# STM32F405RGT6 register map
Vendor: STMicroelectronics; File version: 0.1.0
CPU: Cortex-M4 r0p1, little endian, MPU, FPU, DSP, VTOR, 4 interrupt priority bits
Registers are 32-bit, read-write, reset 0x0 unless marked. A register's access mark holds for its fields unless they carry their own. Offsets are from the block's base; [hi:lo] are bit positions; {n}, {i} and the like mark numbered series.

## RNG — Random number generator
Base 0x50060800
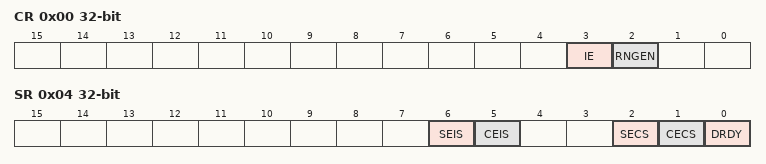
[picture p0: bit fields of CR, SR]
0x00 CR — control register
  [3] IE — Interrupt enable
  [2] RNGEN — Random number generator enable
0x04 SR access per field — status register
  [6] SEIS rw — Seed error interrupt status
  [5] CEIS rw — Clock error interrupt status
  [2] SECS ro — Seed error current status
  [1] CECS ro — Clock error current status
  [0] DRDY ro — Data ready
0x08 DR ro — data register
  [31:0] RNDATA — Random data

## DBGMCU — Debug support
Base 0xE0042000
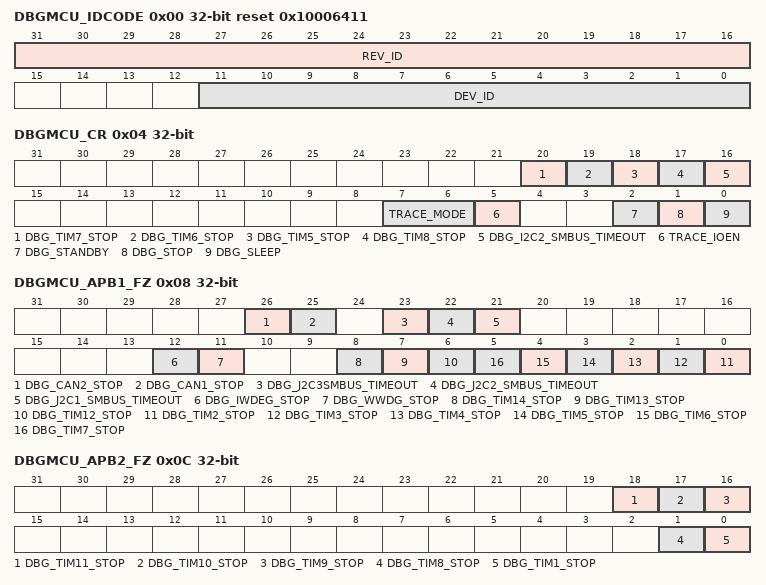
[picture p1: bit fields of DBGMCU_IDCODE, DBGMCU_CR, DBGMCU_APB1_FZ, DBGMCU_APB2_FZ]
0x00 DBGMCU_IDCODE ro reset 0x10006411 — IDCODE
  [31:16] REV_ID, [11:0] DEV_ID
0x04 DBGMCU_CR — Control Register
  [20] DBG_TIM7_STOP, [19] DBG_TIM6_STOP, [18] DBG_TIM5_STOP, [17] DBG_TIM8_STOP, [16] DBG_I2C2_SMBUS_TIMEOUT, [7:6] TRACE_MODE, [5] TRACE_IOEN, [2] DBG_STANDBY, [1] DBG_STOP, [0] DBG_SLEEP
0x08 DBGMCU_APB1_FZ — Debug MCU APB1 Freeze registe
  [26] DBG_CAN2_STOP, [25] DBG_CAN1_STOP, [23] DBG_J2C3SMBUS_TIMEOUT, [22] DBG_J2C2_SMBUS_TIMEOUT, [21] DBG_J2C1_SMBUS_TIMEOUT, [12] DBG_IWDEG_STOP, [11] DBG_WWDG_STOP, [8] DBG_TIM14_STOP, [7] DBG_TIM13_STOP, [6] DBG_TIM12_STOP, [n-2] DBG_TIM{n}_STOP (n=2..7)
0x0C DBGMCU_APB2_FZ — Debug MCU APB2 Freeze registe
  [18] DBG_TIM11_STOP — TIM11 counter stopped when core is halted
  [17] DBG_TIM10_STOP — TIM10 counter stopped when core is halted
  [16] DBG_TIM9_STOP — TIM9 counter stopped when core is halted
  [1] DBG_TIM8_STOP — TIM8 counter stopped when core is halted
  [0] DBG_TIM1_STOP — TIM1 counter stopped when core is halted

## GPIOI — General-purpose I/Os
Base 0x40022000
Same registers: GPIOC 0x40020800, GPIOD 0x40020C00, GPIOE 0x40021000, GPIOF 0x40021400, GPIOG 0x40021800, GPIOH 0x40021C00
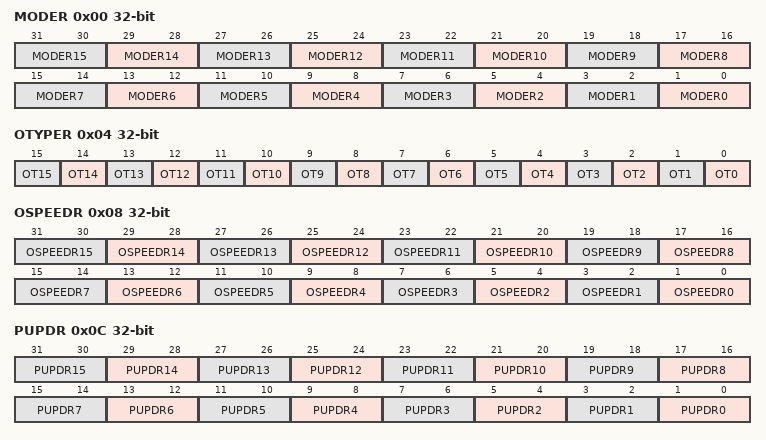
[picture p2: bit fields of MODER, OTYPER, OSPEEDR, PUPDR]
0x00 MODER — GPIO port mode register
  [2n+1:2n] MODER{n} (n=0..15) — Port x configuration bits (y = 0..15)
0x04 OTYPER — GPIO port output type register
  [n] OT{n} (n=0..15) — Port x configuration bits (y = 0..15)
0x08 OSPEEDR — GPIO port output speed register
  [2n+1:2n] OSPEEDR{n} (n=0..15) — Port x configuration bits (y = 0..15)
0x0C PUPDR — GPIO port pull-up/pull-down register
  [2n+1:2n] PUPDR{n} (n=0..15) — Port x configuration bits (y = 0..15)
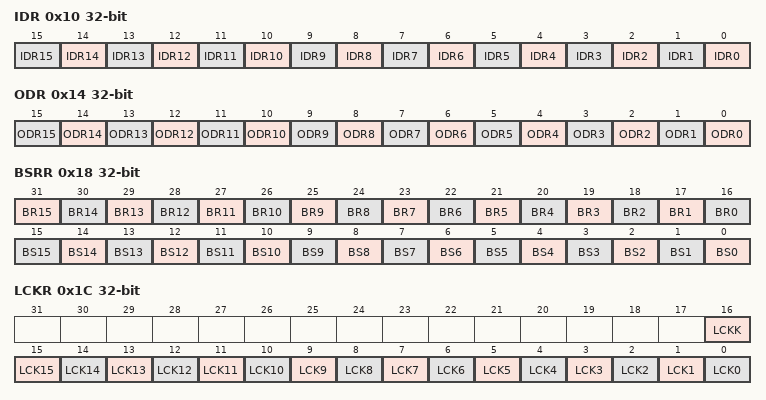
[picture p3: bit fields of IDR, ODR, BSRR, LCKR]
0x10 IDR ro — GPIO port input data register
  [n] IDR{n} (n=0..15) — Port input data (y = 0..15)
0x14 ODR — GPIO port output data register
  [n] ODR{n} (n=0..15) — Port output data (y = 0..15)
0x18 BSRR wo — GPIO port bit set/reset register
  [n+16] BR{n} (n=1..15) — Port x reset bit y (y = 0..15)
  [16] BR0 — Port x set bit y (y= 0..15)
  [n] BS{n} (n=0..15) — Port x set bit y (y= 0..15)
0x1C LCKR — GPIO port configuration lock register
  [16] LCKK — Port x lock bit y (y= 0..15)
  [n] LCK{n} (n=0..15) — Port x lock bit y (y= 0..15)
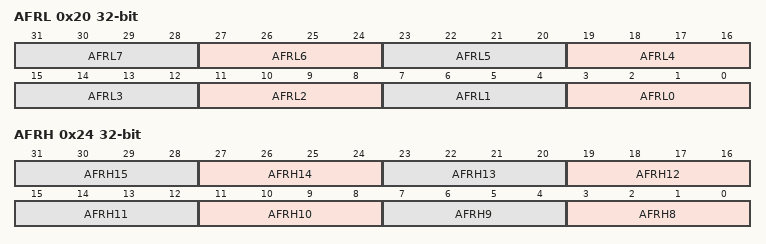
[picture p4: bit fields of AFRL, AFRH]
0x20 AFRL — GPIO alternate function low register
  [4n+3:4n] AFRL{n} (n=0..7) — Alternate function selection for port x bit y (y = 0..7)
0x24 AFRH — GPIO alternate function high register
  [4n-29:4n-32] AFRH{n} (n=8..15) — Alternate function selection for port x bit y (y = 8..15)

## GPIOB — General-purpose I/Os
Base 0x40020400
Registers as GPIOI; these are added or differ:
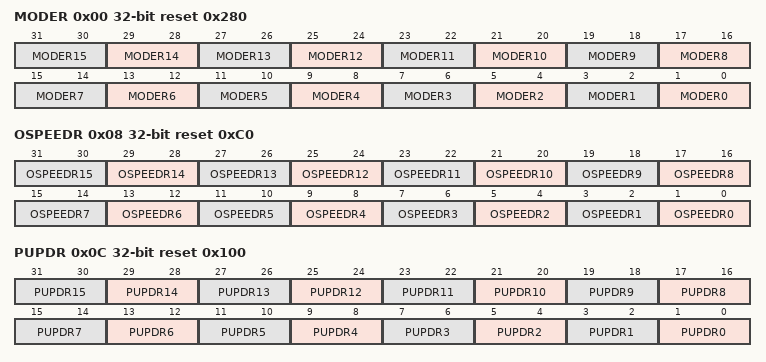
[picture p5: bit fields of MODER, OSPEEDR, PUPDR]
0x00 MODER reset 0x280 — GPIO port mode register
  [2n+1:2n] MODER{n} (n=0..15) — Port x configuration bits (y = 0..15)
0x08 OSPEEDR reset 0xC0 — GPIO port output speed register
  [2n+1:2n] OSPEEDR{n} (n=0..15) — Port x configuration bits (y = 0..15)
0x0C PUPDR reset 0x100 — GPIO port pull-up/pull-down register
  [2n+1:2n] PUPDR{n} (n=0..15) — Port x configuration bits (y = 0..15)

## GPIOA — General-purpose I/Os
Base 0x40020000
Registers as GPIOI; these are added or differ:
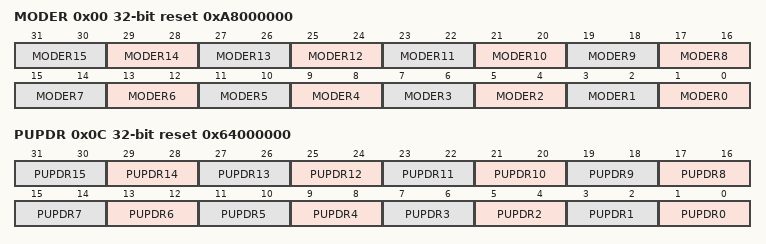
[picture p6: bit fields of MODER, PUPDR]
0x00 MODER reset 0xA8000000 — GPIO port mode register
  [2n+1:2n] MODER{n} (n=0..15) — Port x configuration bits (y = 0..15)
0x0C PUPDR reset 0x64000000 — GPIO port pull-up/pull-down register
  [2n+1:2n] PUPDR{n} (n=0..15) — Port x configuration bits (y = 0..15)
